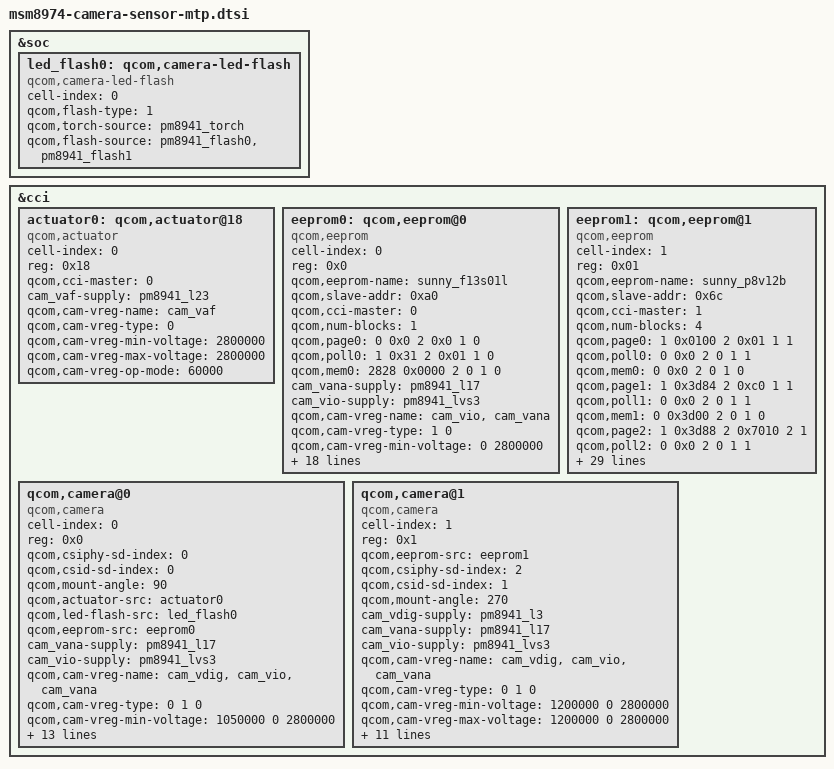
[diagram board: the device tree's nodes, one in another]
/*
 * Copyright (c) 2012-2014, The Linux Foundation. All rights reserved.
 *
 * This program is free software; you can redistribute it and/or modify
 * it under the terms of the GNU General Public License version 2 and
 * only version 2 as published by the Free Software Foundation.
 *
 * This program is distributed in the hope that it will be useful,
 * but WITHOUT ANY WARRANTY; without even the implied warranty of
 * MERCHANTABILITY or FITNESS FOR A PARTICULAR PURPOSE.  See the
 * GNU General Public License for more details.
 */

&soc {
	led_flash0: qcom,camera-led-flash {
		cell-index = <0>;
		compatible = "qcom,camera-led-flash";
		qcom,flash-type = <1>;
		qcom,torch-source = <&pm8941_torch>;
		qcom,flash-source = <&pm8941_flash0 &pm8941_flash1>;
	};
};

&cci {
	actuator0: qcom,actuator@18 {
		cell-index = <0>;
		reg = <0x18>;
		compatible = "qcom,actuator";
		qcom,cci-master = <0>;
		cam_vaf-supply = <&pm8941_l23>;
		qcom,cam-vreg-name = "cam_vaf";
		qcom,cam-vreg-type = <0>;
		qcom,cam-vreg-min-voltage = <2800000>;
		qcom,cam-vreg-max-voltage = <2800000>;
		qcom,cam-vreg-op-mode = <60000>;
	};

	/* oneplus 2015-5-30 longxiaowu@camera porting start for s5k3m2 */
	eeprom0: qcom,eeprom@0 {
		cell-index = <0>;
		reg = <0x0>;
		qcom,eeprom-name = "sunny_f13s01l";
		compatible = "qcom,eeprom";
		qcom,slave-addr = <0xa0>;
		qcom,cci-master = <0>;
		qcom,num-blocks = <1>;

		qcom,page0 = <0 0x0 2 0x0 1 0>;
		qcom,poll0 = <1 0x31 2 0x01 1 0>;
		qcom,mem0 = <2828 0x0000 2 0 1 0>;

		cam_vana-supply = <&pm8941_l17>;
		cam_vio-supply = <&pm8941_lvs3>;
		qcom,cam-vreg-name = "cam_vio", "cam_vana";
		qcom,cam-vreg-type = <1 0>;
		qcom,cam-vreg-min-voltage = <0 2800000>;
		qcom,cam-vreg-max-voltage = <0 2800000>;
		qcom,cam-vreg-op-mode = <0 100000>;
		qcom,gpio-no-mux = <0>;
		gpios = <&msmgpio 15 0>,
			<&msmgpio 90 0>,
			<&msmgpio 57 0>;
		qcom,gpio-reset = <1>;
		qcom,gpio-vdig = <2>;
		qcom,gpio-req-tbl-num = <0 1 2>;
		qcom,gpio-req-tbl-flags = <1 0 0>;
		qcom,gpio-req-tbl-label = "CAMIF_MCLK0",
					  "CAM_RESET0",
					  "CAM_VDIG0";
		qcom,cam-power-seq-type = "sensor_vreg", "sensor_vreg", "sensor_gpio",
			"sensor_gpio", "sensor_clk";
		qcom,cam-power-seq-val = "cam_vana", "cam_vio",  "sensor_gpio_vdig",
			"sensor_gpio_reset","sensor_cam_mclk";
		qcom,cam-power-seq-cfg-val = <1 1 1 1 24000000>;
		qcom,cam-power-seq-delay = <1 1 1 5 5>;
		status = "ok";
	};
/* oneplus 2015-5-30 longxiaowu@camera porting end for s5k3m2 */

/* oneplus 2015-5-30 longxiaowu@camera porting end for ov8858 */
	eeprom1: qcom,eeprom@1 {
		cell-index = <1>;
		reg = <0x01>;
		qcom,eeprom-name = "sunny_p8v12b";
		compatible = "qcom,eeprom";
		qcom,slave-addr = <0x6c>;
		qcom,cci-master = <1>;
		qcom,num-blocks = <4>;

		qcom,page0 = <1 0x0100 2 0x01 1 1>;
		qcom,poll0 = <0 0x0 2 0 1 1>;
		qcom,mem0 = <0 0x0 2 0 1 0>;

		qcom,page1 = <1 0x3d84 2 0xc0 1 1>;
		qcom,poll1 = <0 0x0 2 0 1 1>;
		qcom,mem1 = <0 0x3d00 2 0 1 0>;

		qcom,page2 = <1 0x3d88 2 0x7010 2 1>;
		qcom,poll2 = <0 0x0 2 0 1 1>;
		qcom,mem2 = <0 0x3d00 2 0 1 0>;

		qcom,page3 = <1 0x3d8A 2 0x720a 2 1>;
		qcom,pageen3 = <1 0x3d81 2 0x01 1 10>;
		qcom,poll3 = <0 0x0 2 0 1 1>;
		qcom,mem3 = <507 0x7010 2 0 1 1>;

		cam_vdig-supply = <&pm8941_l3>;
		cam_vana-supply = <&pm8941_l17>;
		cam_vio-supply = <&pm8941_lvs3>;
		qcom,cam-vreg-name = "cam_vdig", "cam_vio", "cam_vana";
		qcom,cam-vreg-type = <0 1 0>;
		qcom,cam-vreg-min-voltage = <1200000 0 2800000>;
		qcom,cam-vreg-max-voltage = <1200000 0 2800000>;
		qcom,cam-vreg-op-mode = <100000 0 80000>;
		gpios = <&msmgpio 17 0>,
			<&msmgpio 18 0>,
			<&msmgpio 89 0>;
		qcom,gpio-reset = <1>;
		qcom,gpio-standby = <2>;
		qcom,gpio-req-tbl-num = <0 1 2>;
		qcom,gpio-req-tbl-flags = <1 0 0>;
		qcom,gpio-req-tbl-label = "CAMIF_MCLK1",
					  "CAM_RESET1",
					  "CAM_STANDBY";
		qcom,cam-power-seq-type = "sensor_vreg", "sensor_gpio", "sensor_vreg",
			"sensor_vreg", "sensor_gpio", "sensor_clk";
		qcom,cam-power-seq-val = "cam_vio", "sensor_gpio_standby",  "cam_vana",
			"cam_vdig", "sensor_gpio_reset","sensor_cam_mclk";
		qcom,cam-power-seq-cfg-val = <1 1 1 1 1 24000000>;
		qcom,cam-power-seq-delay = <1 1 1 1 5 5>;
		status = "ok";
	};
/* oneplus 2015-5-30 longxiaowu@camera porting end for ov8858 */

/* oneplus 2015-5-20 longxiaowu@camera porting start for 15055 */
	qcom,camera@0 {
		cell-index = <0>;
		compatible = "qcom,camera";
		reg = <0x0>;
		qcom,csiphy-sd-index = <0>;
		qcom,csid-sd-index = <0>;
		qcom,mount-angle = <90>;
		qcom,actuator-src = <&actuator0>;
		qcom,led-flash-src = <&led_flash0>;
		qcom,eeprom-src = <&eeprom0>;
		cam_vana-supply = <&pm8941_l17>;
		cam_vio-supply = <&pm8941_lvs3>;
		qcom,cam-vreg-name = "cam_vdig", "cam_vio", "cam_vana";
		qcom,cam-vreg-type = <0 1 0>;
		qcom,cam-vreg-min-voltage = <1050000 0 2800000>;
		qcom,cam-vreg-max-voltage = <1050000 0 2800000>;
		qcom,cam-vreg-op-mode = <0 0 100000>;
		qcom,gpio-no-mux = <0>;
		gpios = <&msmgpio 15 0>,
			<&msmgpio 90 0>,
			<&msmgpio 57 0>;
		qcom,gpio-reset = <1>;
		qcom,gpio-vdig = <2>;
		qcom,gpio-req-tbl-num = <0 1 2>;
		qcom,gpio-req-tbl-flags = <1 0 0>;
		qcom,gpio-req-tbl-label = "CAMIF_MCLK0",
					  "CAM_RESET0",
					  "CAM_VDIG0";
		qcom,sensor-position = <0>;
		qcom,sensor-mode = <0>;
		qcom,cci-master = <0>;
		status = "ok";
	};

	qcom,camera@1 {
		cell-index = <1>;
		compatible = "qcom,camera";
		reg = <0x1>;
		qcom,eeprom-src = <&eeprom1>;
		qcom,csiphy-sd-index = <2>;
		qcom,csid-sd-index = <1>;
		qcom,mount-angle = <270>;
		cam_vdig-supply = <&pm8941_l3>;
		cam_vana-supply = <&pm8941_l17>;
		cam_vio-supply = <&pm8941_lvs3>;
		qcom,cam-vreg-name = "cam_vdig", "cam_vio", "cam_vana";
		qcom,cam-vreg-type = <0 1 0>;
		qcom,cam-vreg-min-voltage = <1200000 0 2800000>;
		qcom,cam-vreg-max-voltage = <1200000 0 2800000>;
		qcom,cam-vreg-op-mode = <100000 0 60000>;
		gpios = <&msmgpio 17 0>,
			<&msmgpio 18 0>,
			<&msmgpio 89 0>;
		qcom,gpio-reset = <1>;
		qcom,gpio-standby = <2>;
		qcom,gpio-req-tbl-num = <0 1 2>;
		qcom,gpio-req-tbl-flags = <1 0 0>;
		qcom,gpio-req-tbl-label = "CAMIF_MCLK1",
					  "CAM_RESET1",
					  "CAM_STANDBY";
		qcom,sensor-position = <1>;
		qcom,sensor-mode = <1>;
		qcom,cci-master = <1>;
		status = "ok";
	};
};
/* oneplus 2015-5-20 longxiaowu@camera porting end for 15055 */
